# EHRPWM0_EPWM register map
Vendor: Texas Instruments
Peripheral module from a debugger description file (folder J7VCL).
Registers are 16-bit, access per field, reset 0x0 unless marked. A register's access mark holds for its fields unless they carry their own. Offsets are as the file gives them; lines under a group give offsets from that group; [hi:lo] are bit positions; {n}, {i} and the like mark numbered series; 'fields as' and 'values as' point back to an identical list; <NAME> marks a mode.

## EHRPWM0_EPWM
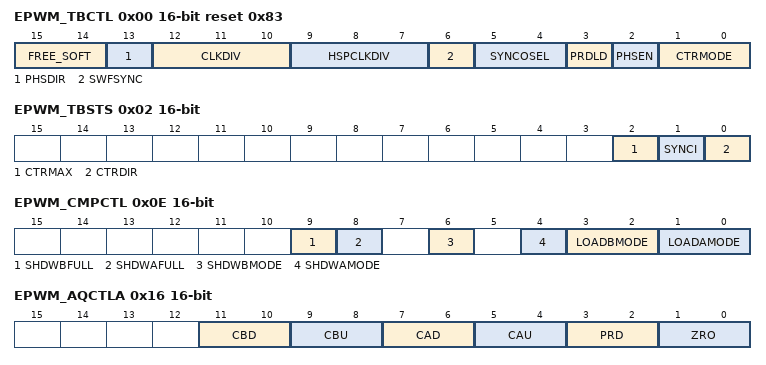
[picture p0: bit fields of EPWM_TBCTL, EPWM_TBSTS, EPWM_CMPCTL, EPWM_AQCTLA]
0x00 EPWM_TBCTL rw reset 0x83
  [15:14] FREE_SOFT — Emulation Mode Bits These bits select the behavior of the EPWM time-base counter during emulation events. 0h: Stop after the next time-base counter increment or decrement 1h: Stop when counter completes a whole cycle 2h: Free run 3h: Free run
  [13] PHSDIR — Phase Direction Bit This bit is only used when the time-base counter is configured in the up-down-count mode. The PHSDIR bit indicates the direction the time-base counter ( 0h: Count down after the synchronization event 1h: Count up after the synchronization event
  [12:10] CLKDIV — Time-base Clock Prescale Bits These bits determine part of the time-base clock prescale value. TBCLK = SYSCLKOUT / (HSPCLKDIV × CLKDIV) 0h: /1 (default on reset) 1h: /2 2h: /4 3h: /8 4h: /16 5h: /32 6h: /64 7h: /128
  [9:7] HSPCLKDIV — High-Speed Time-base Clock Prescale Bits These bits determine part of the time-base clock prescale value. TBCLK = SYSCLKOUT / (HSPCLKDIV × CLKDIV). 0h: /1 1h: /2 (default on reset) 2h: /4 3h: /6 4h: /8 5h: /10 6h: /12 7h: /14
  [6] SWFSYNC — Software Forced Synchronization Pulse 0h: Writing a 0h has no effect and reads always return a 0h. 1h: Writing a 1h forces a one-time synchronization pulse to be generated. This event is ORed with the EPWMxSYNCI input of the EPWM module. SWFSYNC is valid (operates) only when EPWMxSYNCI is selected by SYNCOSEL = 0h.
  [5:4] SYNCOSEL — Synchronization Output Select These bits select the source of the EPWMxSYNCO signal. 0h: EPWMxSYNC 1h: TBCNT = 0: Time-base counter equal to zero ( 2h: TBCNT = CMPB: Time-base counter equal to counter-compare B ( 3h: Disable EPWMxSYNCO signal
  [3] PRDLD — Active Period Register Load From Shadow Register Select 0h: The period register ( 1h: Load the
  [2] PHSEN — Counter Register Load From Phase Register Enable 0h: Do not load the time-base counter ( 1h: Load the time-base counter with the phase register when an EPWMxSYNCI input signal occurs or when a software synchronization is forced by the SWFSYNC bit.
  [1:0] CTRMODE — Counter Mode The time-base counter mode is normally configured once and not changed during normal operation. If you change the mode of the counter, the change will take effect at the next TBCLK edge and the current counter value shall increment or decrement from the value before the mode change. These bits set the time-base counter mode of operation as follows: 0h: Up-count mode 1h: Down-count mode 2h: Up-down-count mode 3h: Stop-freeze counter operation (default on reset)
0x02 EPWM_TBSTS access not given
  [2] CTRMAX — Time-Base Counter Max Latched Status Bit 0h = Reading a 0h indicates the time-base counter never reached its maximum value. Writing a 0h will have no effect. 1h = Reading a 1h on this bit indicates that the time-base counter reached the max value - 0xFFFF. Writing a 1h to this bit will clear the latched event. (access RW1C)
  [1] SYNCI — Input Synchronization Latched Status Bit 0h = Writing a 0h will have no effect. Reading a 0h indicates no external synchronization event has occurred. 1h = Reading a 1h on this bit indicates that an external synchronization event has occurred (EPWMxSYNCI). Writing a 1h to this bit will clear the latched event. (access RW1C)
  [0] CTRDIR ro — Time-Base Counter Direction Status Bit At reset, the counter is frozen, therefore, this bit has no meaning. To make this bit meaningful, you must first set the appropriate mode via the 0h = Time-Base Counter is currently counting down 1h = Time-Base Counter is currently counting up
0x04 HRPWM_TBPHSHR
  [15:8] TBPHSH rw — Time-base phase high-resolution bits
0x06 EPWM_TBPHS rw — This register is only available on ePWM instances that include the high-resolution PWM (HRPWM) extension, otherwise, this location is reserved.
  [15:0] TBPHS — These bits set time-base counter phase of the selected ePWM relative to the time-base that is supplying the synchronization input signal: [a] If [b] If These bits set time-base counter phase of the selected EPWM relative to the time-base that is supplying the synchronization input signal.
0x08 EPWM_TBCNT rw
  [15:0] TBCNT — Reading these bits gives the current time-base counter value. Writing to these bits sets the current time-base counter value. The update happens as soon as the write occurs. The write is NOT synchronized to the time-base clock (TBCLK) and the register is not shadowed.
0x0A EPWM_TBPRD rw
  [15:0] TBPRD — These bits determine the period of the time-base counter. This sets the PWM frequency. Shadowing of this register is enabled and disabled by the
0x0E EPWM_CMPCTL
  [9] SHDWBFULL ro — Counter-compare B ( This bit self clears once a load-strobe occurs. 0h = CMPB shadow FIFO not full yet 1h = Indicates the CMPB shadow FIFO is full. A CPU write will overwrite current shadow value.
  [8] SHDWAFULL ro — Counter-compare A ( 0h = CMPA shadow FIFO not full yet 1h = Indicates the CMPA shadow FIFO is full, a CPU write will overwrite the current shadow value
  [6] SHDWBMODE rw — Counter-compare B ( 0h = Shadow mode. Operates as a double buffer. All writes via the CPU access the shadow register. 1h = Immediate mode. Only the active compare B register is used. All writes and reads directly access the active register for immediate compare action.
  [4] SHDWAMODE rw — Counter-compare A ( 0h = Shadow mode. Operates as a double buffer. All writes via the CPU access the shadow register. 1h = Immediate mode. Only the active compare register is used. All writes and reads directly access the active register for immediate compare action.
  [3:2] LOADBMODE rw — Active Counter-Compare B ( This bit has no effect in immediate mode ( 0h = Load on 1h = Load on 2h = Load on either 3h = Freeze (no loads possible)
  [1:0] LOADAMODE rw — Active Counter-Compare A ( This bit has no effect in immediate mode ( 0h = Load on TBCNT = 0h: Time-base counter equal to zero ( 1h = Load on TBCNT = TBPRD: Time-base counter equal to period ( 2h = Load on either 3h = Freeze (no loads possible)
0x10 HRPWM_CMPAHR — This register is only available on ePWM instances that include the high-resolution PWM (HRPWM) extension; otherwise, this location is reserved.
  [15:8] CMPAHR rw — Compare A High-Resolution register bits for MEP step control. A minimum value of 1h is needed to enable HRPWM capabilities. Valid MEP range of operation: 1h to 255h.
0x12 EPWM_CMPA rw
  [15:0] CMPA — The value in the activeWhen the values are equal, the counter-compare module generates a 'Time-Base counter equal to counter compare A' event. This event is sent to the action-qualifier where it is qualified and converted it into one or more actions. These actions can be applied to either the EPWMxA or the EPWMxB output depending on the configuration of the EPWM_AQCTLA and EPWM_AQCTLB registers. The actions that can be defined in the EPWM_AQCTLA and EPWM_AQCTLB registers include the following. (a) Do nothing the event is ignored. (b) Clear: Pull the EPWMxA and/or EPWMxB signal low. (c) Set: Pull the EPWMxA and/or EPWMxB signal high. (d) Toggle the EPWMxA and/or EPWMxB signal. Shadowing of this register is enabled and disabled by the EPWM_CMPCTL[4] SHDWAMODE bit. By default this register is shadowed. (a) If EPWM_CMPCTL[4] SHDWAMODE = 0h, then the shadow is enabled and any write or read will automatically go to the shadow register. In this case, the EPWM_CMPCTL[1-0] LOADAMODE bit field determines which event will load the active register from the shadow register. (b) Before a write, the EPWM_CMPCTL[8] SHDWAFULL bit can be read to determine if the shadow register is currently full. (c) If EPWM_CMPCTL[4] SHDWAMODE = 1h, then the shadow register is disabled and any write or read will go directly to the active register, that is the register actively controlling the hardware. (d) In either mode, the active and shadow registers share the same memory map address.
0x14 EPWM_CMPB rw
  [15:0] CMPB — The value in the activeWhen the values are equal, the counter-compare module generates a 'time-base counter equal to counter compare B' event. This event is sent to the action-qualifier where it is qualified and converted it into one or more actions. These actions can be applied to either the EPWMxA or the EPWMxB output depending on the configuration of the EPWM_AQCTLA and EPWM_AQCTLB registers. The actions that can be defined in the EPWM_AQCTLA and EPWM_AQCTLB registers include the following. (a) Do nothing, the event is ignored. (b) Clear: Pull the EPWMxA and/or EPWMxB signal low. (c) Set: Pull the EPWMxA and/or EPWMxB signal high. (d) Toggle the EPWMxA and/or EPWMxB signal. Shadowing of this register is enabled and disabled by the EPWM_CMPCTL[6] SHDWBMODE bit. By default this register is shadowed. (a) If EPWM_CMPCTL[6] SHDWBMODE = 0h, then the shadow is enabled and any write or read will automatically go to the shadow register. In this case, the EPWM_CMPCTL[3-2] LOADBMODE bit field determines which event will load the active register from the shadow register: (b) Before a write, the EPWM_CMPCTL[9] SHDWBFULL bit can be read to determine if the shadow register is currently full. (c) If EPWM_CMPCTL[6] SHDWBMODE = 1h, then the shadow register is disabled and any write or read will go directly to the active register, that is the register actively controlling the hardware. (d) In either mode, the active and shadow registers share the same memory map address.
0x16 EPWM_AQCTLA
  [11:10] CBD rw — Action when the Time-Base counter equals the active 0h = Do nothing (action disabled) 1h = Clear: force EPWMxA output low 2h = Set: force EPWMxA output high 3h = Toggle EPWMxA output: low output signal will be forced high, and a high signal will be forced low
  [9:8] CBU rw — Action when the counter equals the active 0h = Do nothing (action disabled) 1h = Clear: force EPWMxA output low 2h = Set: force EPWMxA output high 3h = Toggle EPWMxA output: low output signal will be forced high, and a high signal will be forced low
  [7:6] CAD rw — Action when the counter equals the active 0h = Do nothing (action disabled) 1h = Clear: force EPWMxA output low 2h = Set: force EPWMxA output high 3h = Toggle EPWMxA output: low output signal will be forced high, and a high signal will be forced low
  [5:4] CAU rw — Action when the counter equals the active 0h = Do nothing (action disabled) 1h = Clear: force EPWMxA output low 2h = Set: force EPWMxA output high 3h = Toggle EPWMxA output: low output signal will be forced high, and a high signal will be forced low
  [3:2] PRD rw — Action when the counter equals the period. Note: By definition, in count up-down mode when the counter equals period the direction is defined as 0 or counting down. 0h = Do nothing (action disabled) 1h = Clear: force EPWMxA output low 2h = Set: force EPWMxA output high 3h = Toggle EPWMxA output: low output signal will be forced high, and a high signal will be forced low
  [1:0] ZRO rw — Action when counter equals zero. Note: By definition, in count up-down mode when the counter equals 0 the direction is defined as 1 or counting up. 0h = Do nothing (action disabled) 1h = Clear: force EPWMxA output low 2h = Set: force EPWMxA output high 3h = Toggle EPWMxA output: low output signal will be forced high, and a high signal will be forced low
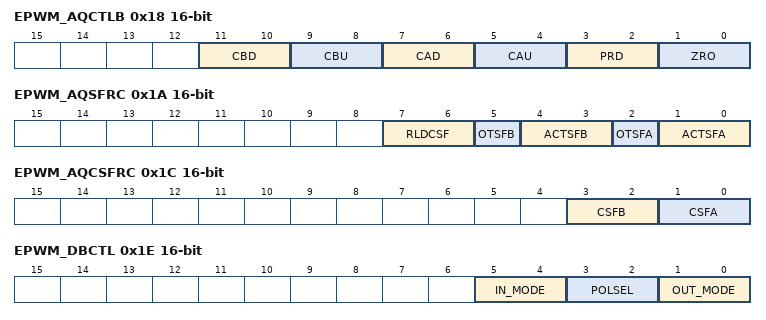
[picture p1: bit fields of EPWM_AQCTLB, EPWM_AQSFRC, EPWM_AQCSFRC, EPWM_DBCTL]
0x18 EPWM_AQCTLB
  [11:10] CBD rw — Action when the counter equals the active 0h = Do nothing (action disabled) 1h = Clear: force EPWMxB output low 2h = Set: force EPWMxB output high 3h = Toggle EPWMxB output: low output signal will be forced high, and a high signal will be forced low
  [9:8] CBU rw — Action when the counter equals the active 0h = Do nothing (action disabled) 1h = Clear: force EPWMxB output low 2h = Set: force EPWMxB output high 3h = Toggle EPWMxB output: low output signal will be forced high, and a high signal will be forced low
  [7:6] CAD rw — Action when the counter equals the active 0h = Do nothing (action disabled) 1h = Clear: force EPWMxB output low 2h = Set: force EPWMxB output high 3h = Toggle EPWMxB output: low output signal will be forced high, and a high signal will be forced low
  [5:4] CAU rw — Action when the counter equals the active 0h = Do nothing (action disabled) 1h = Clear: force EPWMxB output low 2h = Set: force EPWMxB output high 3h = Toggle EPWMxB output: low output signal will be forced high, and a high signal will be forced low
  [3:2] PRD rw — Action when the counter equals the period. Note: By definition, in count up-down mode when the counter equals period the direction is defined as 0 or counting down. 0h = Do nothing (action disabled) 1h = Clear: force EPWMxB output low 2h = Set: force EPWMxB output high 3h = Toggle EPWMxB output: low output signal will be forced high, and a high signal will be forced low
  [1:0] ZRO rw — Action when counter equals zero. Note: By definition, in count up-down mode when the counter equals 0 the direction is defined as 1 or counting up. 0h = Do nothing (action disabled) 1h = Clear: force EPWMxB output low 2h = Set: force EPWMxB output high 3h = Toggle EPWMxB output: low output signal will be forced high, and a high signal will be forced low
0x1A EPWM_AQSFRC access not given
  [7:6] RLDCSF rw
  [5] OTSFB — One-Time Software Forced Event on Output B 0h = Writing a 0h (zero) has no effect. Always reads back a 0h. This bit is auto cleared once a write to this register is complete, that is, a forced event is initiated. This is a one-shot forced event. It can be overridden by another subsequent event on output B. 1h = Initiates a single s/w forced event (access RW1C)
  [4:3] ACTSFB rw — Action when One-Time Software Force B Is invoked 0h = Does nothing (action disabled) 1h = Clear (low) 2h = Set (high) 3h = Toggle (Low -&gt; High, High -&gt; Low). Note: This action is not qualified by counter direction (CNT_dir)
  [2] OTSFA — One-Time Software Forced Event on Output A 0h = Writing a 0 (zero) has no effect. Always reads back a 0. This bit is auto cleared once a write to this register is complete (that is, a forced event is initiated). 1h = Initiates a single software forced event. (access RW1C)
  [1:0] ACTSFA rw — Action When One-Time Software Force A Is Invoked 0h = Does nothing (action disabled). 1h = Clear (low). 2h = Set (high). 3h = Toggle (Low -&gt; High, High -&gt; Low). Note: This action is not qualified by counter direction (CNT_dir)
0x1C EPWM_AQCSFRC
  [3:2] CSFB rw — Continuous Software Force on Output B In immediate mode, a continuous force takes effect on the next TBCLK edge. In shadow mode, a continuous force takes effect on the next TBCLK edge after a shadow load into the active register. To configure shadow mode, use the 0h = Forcing disabled, that is, has no effect 1h = Forces a continuous low on output B 2h = Forces a continuous high on output B 3h = Software forcing is disabled and has no effect
  [1:0] CSFA rw — Continuous Software Force on Output A In immediate mode, a continuous force takes effect on the next TBCLK edge. In shadow mode, a continuous force takes effect on the next TBCLK edge after a shadow load into the active register. 0h = Forcing disabled, that is, has no effect 1h = Forces a continuous low on output A 2h = Forces a continuous high on output A 3h = Software forcing is disabled and has no effect
0x1E EPWM_DBCTL
  [5:4] IN_MODE rw — Dead Band Input Mode Control Bit 5 controls the S5 switch and bit 4 controls the S4 switch. This allows you to select the input source to the falling-edge and rising-edge delay. To produce classical dead-band waveforms, the default is EPWMxA In is the source for both falling and rising-edge delays. 0h = EPWMxA In (from the action-qualifier) is the source for both falling-edge and rising-edge delay. 1h = EPWMxB In (from the action-qualifier) is the source for rising-edge delayed signal. EPWMxA In (from the action-qualifier) is the source for falling-edge delayed signal. 2h = EPWMxA In (from the action-qualifier) is the source for rising-edge delayed signal. EPWMxB In (from the action-qualifier) is the source for falling-edge delayed signal. 3h = EPWMxB In (from the action-qualifier) is the source for both rising-edge delay and falling-edge delayed signal.
  [3:2] POLSEL rw — Polarity Select Control Bit 3 controls the S3 switch and bit 2 controls the S2 switch. This allows you to selectively invert one of the delayed signals before it is sent out of the dead-band submodule. The following descriptions correspond to classical upper/lower switch control as found in one leg of a digital motor control inverter. These assume that the 0h = Active high (AH) mode. Neither EPWMxA nor EPWMxB is inverted (default). 1h = Active low complementary (ALC) mode. EPWMxA is inverted. 2h = Active high complementary (AHC). EPWMxB is inverted. 3h = Active low (AL) mode. Both EPWMxA and EPWMxB are inverted.
  [1:0] OUT_MODE rw — Dead-band Output Mode Control Bit 1 controls the S1 switch and bit 0 controls the S0 switch. This allows you to selectively enable or bypass the dead-band generation for the falling-edge and rising-edge delay. 0h = Dead-band generation is bypassed for both output signals. In this mode, both the EPWMxA and EPWMxB output signals from the action-qualifier are passed directly to the PWM-chopper submodule. In this mode, the POLSEL and IN_MODE bits have no effect. 1h = Disable rising-edge delay. The EPWMxA signal from the action-qualifier is passed straight through to the EPWMxA input of the PWM-chopper submodule. The falling-edge delayed signal is seen on output EPWMxB. The input signal for the delay is determined by the 2h = Disable falling-edge delay. The EPWMxB signal from the action-qualifier is passed straight through to the EPWMxB input of the PWM-chopper submodule. The rising-edge delayed signal is seen on output EPWMxA. The input signal for the delay is determined by the 3h = Dead-band is fully enabled for both rising-edge delay on output EPWMxA and falling-edge delay on output EPWMxB. The input signal for the delay is determined by the
0x20 EPWM_DBRED
  [9:0] DEL rw — Rising Edge Delay Count. 10-bit counter.
0x22 EPWM_DBFED
  [9:0] DEL rw — Falling Edge Delay Count. 10-bit counter
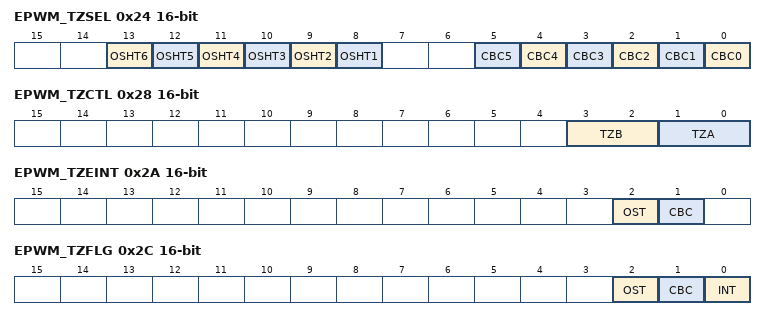
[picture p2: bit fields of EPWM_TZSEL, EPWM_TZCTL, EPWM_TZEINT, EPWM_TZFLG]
0x24 EPWM_TZSEL
  [13] OSHT6 rw — Trip-zone 5 (TZ5) select One-Shot (OSHT) trip-zone enable/disable. When any of the enabled pins go low, a one-shot trip event occurs for this EPWM module. When the event occurs, the action defined in the 0h: Disable TZ5 as a one-shot trip source for this EPWM module 1h: Enable TZ5 as a one-shot trip source for this EPWM module
  [12] OSHT5 rw — Trip-zone 4 (TZ4) select One-Shot (OSHT) trip-zone enable/disable. When any of the enabled pins go low, a one-shot trip event occurs for this EPWM module. When the event occurs, the action defined in the 0h: Disable TZ4 as a one-shot trip source for this EPWM module 1h: Enable TZ4 as a one-shot trip source for this EPWM module
  [11] OSHT4 rw — Trip-zone 3 (TZ3) select One-Shot (OSHT) trip-zone enable/disable. When any of the enabled pins go low, a one-shot trip event occurs for this EPWM module. When the event occurs, the action defined in the 0h: Disable TZ3 as a one-shot trip source for this EPWM module 1h: Enable TZ3 as a one-shot trip source for this EPWM module
  [10] OSHT3 rw — Trip-zone 2 (TZ2) Select One-Shot (OSHT) trip-zone enable/disable. When any of the enabled pins go low, a one-shot trip event occurs for this EPWM module. When the event occurs, the action defined in the 0h: Disable TZ2 as a one-shot trip source for this EPWM module 1h: Enable TZ2 as a one-shot trip source for this EPWM module
  [9] OSHT2 rw — Trip-zone 1 (TZ1) select One-Shot (OSHT) trip-zone enable/disable. When any of the enabled pins go low, a one-shot trip event occurs for this EPWM module. When the event occurs, the action defined in the 0h: Disable TZ1 as a one-shot trip source for this EPWM module 1h: Enable TZ1 as a one-shot trip source for this EPWM module
  [8] OSHT1 rw — Trip-zone 0 (TZ0) select One-Shot (OSHT) trip-zone enable/disable. When any of the enabled pins go low, a one-shot trip event occurs for this EPWM module. When the event occurs, the action defined in the 0h: Disable TZ0 as a one-shot trip source for this EPWM module 1h: Enable TZ0 as a one-shot trip source for this EPWM module
  [n] CBC{n} rw (n=0..5) — Trip-zone {n} (TZ{n}) select Cycle-by-Cycle (CBC) trip-zone enable/disable. When any of the enabled pins go low, a cycle-by-cycle trip event occurs for this EPWM module. When the event occurs, the action defined in the 0h: Disable TZ{n} as a CBC trip source for this EPWM module 1h: Enable TZ{n} as a CBC trip source for this EPWM module
0x28 EPWM_TZCTL
  [3:2] TZB rw — When a trip event occurs the following action is taken on output EPWMxB. Which trip-zone pins can cause an event is defined in the 0h = High impedance (EPWMxB = High-impedance state) 1h = Force EPWMxB to a high state 2h = Force EPWMxB to a low state 3h = Do nothing, no action is taken on EPWMxB.
  [1:0] TZA rw — When a trip event occurs the following action is taken on output EPWMxA. Which trip-zone pins can cause an event is defined in the 0h = High impedance (EPWMxA = High-impedance state) 1h = Force EPWMxA to a high state 2h = Force EPWMxA to a low state 3h = Do nothing, no action is taken on EPWMxA.
0x2A EPWM_TZEINT
  [2] OST rw — Trip-zone One-Shot Interrupt Enable 0h = Disable one-shot interrupt generation 1h = Enable Interrupt generation
  [1] CBC rw — Trip-zone Cycle-by-Cycle Interrupt Enable 0h = Disable cycle-by-cycle interrupt generation 1h = Enable interrupt generation
0x2C EPWM_TZFLG ro
  [2] OST — Latched Status Flag for A One-Shot Trip Event 0h = No one-shot trip event has occurred 1h = Indicates a trip event has occurred on a pin selected as a one-shot trip source. This bit is cleared by writing the appropriate value to the
  [1] CBC — Latched Status Flag for Cycle-By-Cycle Trip Event 0h = No cycle-by-cycle trip event has occurred 1h = Indicates a trip event has occurred on a pin selected as a cycle-by-cycle trip source. The
  [0] INT — Latched Trip Interrupt Status Flag 0h = Indicates no interrupt has been generated 1h = Indicates an EPWMxTZINT interrupt was generated because of a trip condition. No further EPWMxTZINT interrupts will be generated until this flag is cleared. If the interrupt flag is cleared when either CBC or OST is set, then another interrupt pulse will be generated. Clearing all flag bits will prevent further interrupts. This bit is cleared by writing the appropriate value to the
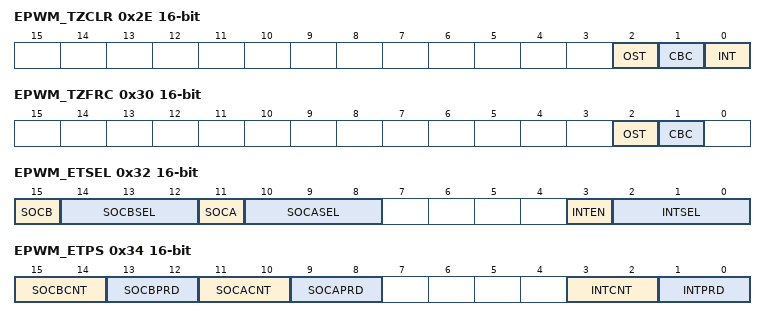
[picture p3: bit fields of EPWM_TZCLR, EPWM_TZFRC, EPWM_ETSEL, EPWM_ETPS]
0x2E EPWM_TZCLR
  [2] OST rw — Clear Flag for One-Shot Trip (OST) Latch 0h = Has no effect. Always reads back a 0h 1h = Clears this Trip (set) condition
  [1] CBC rw — Clear Flag for Cycle-By-Cycle (CBC) Trip Latch 0h = Has no effect. Always reads back a 0h 1h = Clears this Trip (set) condition
  [0] INT rw — Global Interrupt Clear Flag 0h = Has no effect. Always reads back a 0h 1h = Clears the trip-interrupt flag for this EPWM module ( Note: No further EPWMxTZINT interrupts will be generated until the flag is cleared. If the
0x30 EPWM_TZFRC
  [2] OST rw — Force a One-Shot Trip Event via Software 0h = Writing of 0h is ignored. Always reads back a 0h. 1h = Forces a one-shot trip event and sets the
  [1] CBC rw — Force a Cycle-by-Cycle Trip Event via Software 0h = Writing of 0h is ignored. Always reads back a 0h. 1h = Forces a cycle-by-cycle trip event and sets the
0x32 EPWM_ETSEL
  [15] SOCB rw — Enable SOCB pulse when set to 1h.
  [14:12] SOCBSEL rw — EPWMxSOCB Selection Options 0h: Reserved 1h: Enable event time-base counter equal to zero (CNT_zero event) 2h: Enable event time-base counter equal to period (PRD_eq event) 3h: Reserved 4h: Enable event time-base counter equal to CMPA when the timer is incrementing (CMPA_eq_UC event) 5h: Enable event time-base counter equal to CMPA when the timer is decrementing (CMPA_eq_DC event) 6h: Enable event time-base counter equal to CMPB when the timer is incrementing (CMPB_eq_UC event) 7h: Enable event time-base counter equal to CMPB when the timer is decrementing (CMPB_eq_DC event)
  [11] SOCA rw — Enable SOCA pulse when set to 1h.
  [10:8] SOCASEL rw — EPWMxSOCA Selection Options 0h: Reserved 1h: Enable event time-base counter equal to zero (CNT_zero event) 2h: Enable event time-base counter equal to period (PRD_eq event) 3h: Reserved 4h: Enable event time-base counter equal to CMPA when the timer is incrementing (CMPA_eq_UC event) 5h: Enable event time-base counter equal to CMPA when the timer is decrementing (CMPA_eq_DC event) 6h: Enable event time-base counter equal to CMPB when the timer is incrementing (CMPB_eq_UC event) 7h: Enable event time-base counter equal to CMPB when the timer is decrementing (CMPB_eq_DC event)
  [3] INTEN rw — Enable EPWM Interrupt (EPWMx_INT) Generation 0h: Disable EPWMx_INT generation 1h: Enable EPWMx_INT generation
  [2:0] INTSEL rw — EPWM Interrupt (EPWMx_INT) Selection Options 0h: Reserved 1h: Enable event time-base counter equal to zero. ( 2h: Enable event time-base counter equal to period ( 3h: Reserved 4h: Enable event time-base counter equal to CMPA when the timer is incrementing 5h: Enable event time-base counter equal to CMPA when the timer is decrementing 6h: Enable event time-base counter equal to CMPB when the timer is incrementing 7h: Enable event time-base counter equal to CMPB when the timer is decrementing
0x34 EPWM_ETPS
  [15:14] SOCBCNT ro — EPWMxSOCB Counter Register These bits indicate how many selected events have occurred.
  [13:12] SOCBPRD rw — EPWMxSOCB Period Select These bits select how many selected event need to occur before an SOCB pulse is generated.
  [11:10] SOCACNT ro — EPWMxSOCA Counter Register These bits indicate how many selected events have occurred.
  [9:8] SOCAPRD rw — EPWMxSOCA Period Select These bits select how many selected event need to occur before an SOCA pulse is generated.
  [3:2] INTCNT ro — EPWM Interrupt Event (EPWMx_INT) Counter Register These bits indicate how many selected 0h: No events have occurred 1h: 1 event has occurred 2h: 2 events have occurred 3h: 3 events have occurred
  [1:0] INTPRD rw — EPWM Interrupt (EPWMx_INT) Period Select These bits determine how many selected 0h: Disable the interrupt event counter. No interrupt will be generated and the 1h: Generate an interrupt on the first event INTCNT = 0b01 (first event) 2h: Generate interrupt on the 3h: Generate interrupt on the
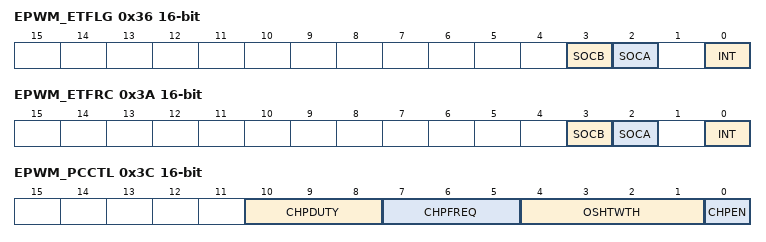
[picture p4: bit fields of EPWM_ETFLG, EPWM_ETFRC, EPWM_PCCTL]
0x36 EPWM_ETFLG ro
  [3] SOCB — Latched SOCB Flag Bit Status 0h: Indicates no event occurred 1h: Indicates that a start of conversion pulse was generated on EPWMxSOCB Note: Unlike the INT flag bit, the EPWMxSOCB output will continue to pulse even if the flag bit is set.
  [2] SOCA — Latched SOCA Flag Bit Status 0h: Indicates no event occurred 1h: Indicates that a start of conversion pulse was generated on EPWMxSOCA Note: Unlike the INT flag bit, the EPWMxSOCA output will continue to pulse even if the flag bit is set.
  [0] INT — Latched EPWM Interrupt (EPWMx_INT) Status Flag 0h: Indicates no event occurred. 1h: Indicates that an EPWMx interrupt (EWPMx_INT) was generated. No further interrupts will be generated until the flag bit is cleared. Up to one interrupt can be pending while the
0x38 EPWM_ETCLR ro
  [0] INT — ePWM Interrupt [EPWMx_INT] Flag Clear Bit
0x3A EPWM_ETFRC
  [3] SOCB rw — SOCB Flag Clear Bit 0h: Writing a 0h has no effect. Always reads back a 0h. 1h: Writing a 1h clears the EPWM_ETFLG[3] SOCB flag bit
  [2] SOCA rw — SOCA Flag Clear Bit 0h: Writing a 0h has no effect. Always reads back a 0h. 1h: Writing a 1h clears the EPWM_ETFLG[2] SOCA flag bit
  [0] INT rw — EPWM Interrupt (EPWMx_INT) Flag Clear Bit 0h: Writing a 0 has no effect. Always reads back a 0h. 1h: Writing 1 clears the
0x3C EPWM_PCCTL
  [10:8] CHPDUTY rw — Chopping Clock Duty Cycle 0h = Duty = 1/8 (12.5%) 1h = Duty = 2/8 (25.0%) 2h = Duty = 3/8 (37.5%) 3h = Duty = 4/8 (50.0%) 4h = Duty = 5/8 (62.5%) 5h = Duty = 6/8 (75.0%) 6h = Duty = 7/8 (87.5%) 7h = Reserved
  [7:5] CHPFREQ rw — Chopping Clock Frequency 0h = Divide by 1 (no prescale) 1h = Divide by 2 2h = Divide by 3 3h = Divide by 4 4h = Divide by 5 5h = Divide by 6 6h = Divide by 7 7h = Divide by 8
  [4:1] OSHTWTH rw — One-Shot Pulse Width 0h = 1 - SYSCLKOUT/8 wide 1h = 2 - SYSCLKOUT/8 wide 2h = 3 - SYSCLKOUT/8 wide 3h = 4 - SYSCLKOUT/8 wide Fh = 16 - SYSCLKOUT/8 wide
  [0] CHPEN rw — PWM-chopping Enable 0h = Disable (bypass) PWM chopping function 1h = Enable chopping function
0x5C EPWM_PID 32-bit ro reset 0x44D10903 — The revision register is used by software to track features, bugs, and compatibility.
  [31:0] REVISION — TI Internal Data Identifies revision of peripheral.
